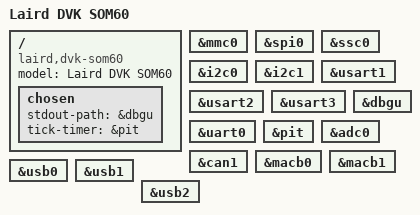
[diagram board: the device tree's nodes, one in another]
// SPDX-License-Identifier: GPL-2.0
/*
 * at91-dvk_som60.dts - Device Tree file for the DVK SOM60 board
 *
 *  Copyright (C) 2018 Laird,
 *		  2018 Ben Whitten <ben.whitten@lairdtech.com>
 *
 */
/dts-v1/;
#include "at91-som60.dtsi"
#include "at91-dvk_su60_somc.dtsi"
#include "at91-dvk_su60_somc_lcm.dtsi"

/ {
	model = "Laird DVK SOM60";
	compatible = "laird,dvk-som60", "laird,som60", "atmel,sama5d36", "atmel,sama5d3", "atmel,sama5";

	chosen {
		stdout-path = &dbgu;
		tick-timer = &pit;
	};
};

&mmc0 {
	status = "okay";
};

&spi0 {
	status = "okay";
};

&ssc0 {
	status = "okay";
};

&i2c0 {
	status = "okay";
};

&i2c1 {
	status = "okay";
};

&usart1 {
	status = "okay";
};

&usart2 {
	status = "okay";
};

&usart3 {
	status = "okay";
};

&uart0 {
	status = "okay";
};

&dbgu {
	status = "okay";
};

&pit {
	status = "okay";
};

&adc0 {
	status = "okay";
};

&can1 {
	status = "okay";
};

&macb0 {
	status = "okay";
};

&macb1 {
	status = "okay";
};

&usb0 {
	status = "okay";
};

&usb1 {
	status = "okay";
};

&usb2 {
	status = "okay";
};

